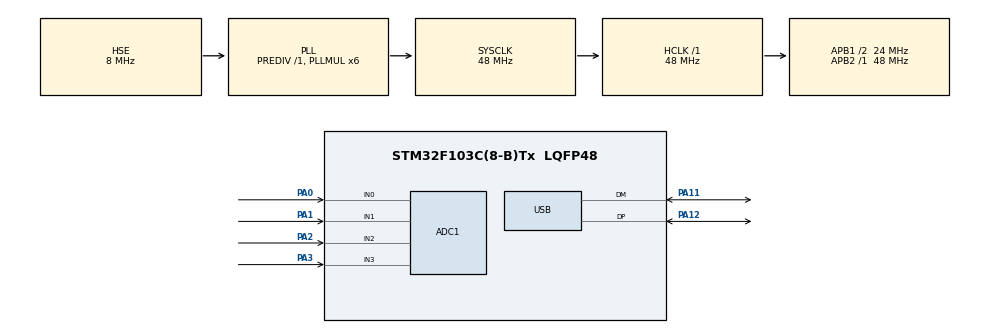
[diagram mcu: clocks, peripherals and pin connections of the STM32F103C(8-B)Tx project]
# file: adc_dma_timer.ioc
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ADC1.Channel-0\#ChannelRegularConversion=ADC_CHANNEL_0
ADC1.Channel-1\#ChannelRegularConversion=ADC_CHANNEL_1
ADC1.Channel-2\#ChannelRegularConversion=ADC_CHANNEL_2
ADC1.Channel-3\#ChannelRegularConversion=ADC_CHANNEL_3
ADC1.ExternalTrigConv=ADC_EXTERNALTRIGCONV_T3_TRGO
ADC1.NbrOfConversion=4
ADC1.NbrOfConversionFlag=1
ADC1.Rank-0\#ChannelRegularConversion=1
ADC1.Rank-1\#ChannelRegularConversion=2
ADC1.Rank-2\#ChannelRegularConversion=3
ADC1.Rank-3\#ChannelRegularConversion=4
ADC1.SamplingTime-0\#ChannelRegularConversion=ADC_SAMPLETIME_7CYCLES_5
ADC1.SamplingTime-1\#ChannelRegularConversion=ADC_SAMPLETIME_28CYCLES_5
ADC1.SamplingTime-2\#ChannelRegularConversion=ADC_SAMPLETIME_55CYCLES_5
ADC1.SamplingTime-3\#ChannelRegularConversion=ADC_SAMPLETIME_239CYCLES_5
ADC1.master=1
Dma.ADC1.0.Direction=DMA_PERIPH_TO_MEMORY
Dma.ADC1.0.Instance=DMA1_Channel1
Dma.ADC1.0.MemDataAlignment=DMA_MDATAALIGN_HALFWORD
Dma.ADC1.0.MemInc=DMA_MINC_ENABLE
Dma.ADC1.0.Mode=DMA_CIRCULAR
Dma.ADC1.0.PeriphDataAlignment=DMA_PDATAALIGN_HALFWORD
Dma.ADC1.0.PeriphInc=DMA_PINC_DISABLE
Dma.ADC1.0.Priority=DMA_PRIORITY_LOW
Dma.Request0=ADC1
Mcu.Family=STM32F1
Mcu.Name=STM32F103C(8-B)Tx
Mcu.Package=LQFP48
NVIC.ADC1_2_IRQn=true\:0\:0\:false\:false\:true\:true\:true\:true
NVIC.DMA1_Channel1_IRQn=true\:0\:0\:false\:false\:true\:false\:true\:true
NVIC.PriorityGroup=NVIC_PRIORITYGROUP_4
NVIC.USB_HP_CAN1_TX_IRQn=true\:0\:0\:false\:false\:true\:true\:true\:true
NVIC.USB_LP_CAN1_RX0_IRQn=true\:0\:0\:false\:false\:true\:false\:true\:true
PA0-WKUP.Signal=ADCx_IN0
PA1.Signal=ADCx_IN1
PA11.Mode=Device
PA11.Signal=USB_DM
PA12.Mode=Device
PA12.Signal=USB_DP
PA2.Signal=ADCx_IN2
PA3.Signal=ADCx_IN3
PD0-OSC_IN.Mode=HSE-External-Oscillator
PD0-OSC_IN.Signal=RCC_OSC_IN
PD1-OSC_OUT.Mode=HSE-External-Oscillator
PD1-OSC_OUT.Signal=RCC_OSC_OUT
ProjectManager.HeapSize=0x200
ProjectManager.StackSize=0x400
ProjectManager.TargetToolchain=STM32CubeIDE
RCC.ADCPresc=RCC_ADCPCLK2_DIV4
RCC.AHBFreq_Value=48000000
RCC.APB1CLKDivider=RCC_HCLK_DIV2
RCC.APB1Freq_Value=24000000
RCC.APB1TimFreq_Value=48000000
RCC.APB2Freq_Value=48000000
RCC.APB2TimFreq_Value=48000000
RCC.HCLKFreq_Value=48000000
RCC.PLLMUL=RCC_PLL_MUL6
RCC.SYSCLKFreq_VALUE=48000000
RCC.SYSCLKSource=RCC_SYSCLKSOURCE_PLLCLK
RCC.USBFreq_Value=48000000
SH.ADCx_IN0.0=ADC1_IN0,IN0
SH.ADCx_IN1.0=ADC1_IN1,IN1
SH.ADCx_IN2.0=ADC1_IN2,IN2
SH.ADCx_IN3.0=ADC1_IN3,IN3
TIM3.Period=1000-1
TIM3.Prescaler=24000-1
TIM3.TIM_MasterOutputTrigger=TIM_TRGO_UPDATE
TIM3.TIM_MasterSlaveMode=TIM_MASTERSLAVEMODE_ENABLE
USB_DEVICE.CLASS_NAME_FS=CDC
USB_DEVICE.PRODUCT_STRING_CDC_FS=STM32 Virtual Port
USB_DEVICE.VirtualMode=Cdc
USB_DEVICE.VirtualModeFS=Cdc_FS
VP_TIM3_VS_ClockSourceINT.Mode=Internal
VP_USB_DEVICE_VS_USB_DEVICE_CDC_FS.Mode=CDC_FS
board=custom

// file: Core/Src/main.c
/* USER CODE BEGIN Header */
/**
  ******************************************************************************
  * @file           : main.c
  * @brief          : Main program body
  ******************************************************************************
  * @attention
  *
  * Copyright (c) 2022 STMicroelectronics.
  * All rights reserved.
  *
  * This software is licensed under terms that can be found in the LICENSE file
  * in the root directory of this software component.
  * If no LICENSE file comes with this software, it is provided AS-IS.
  *
  ******************************************************************************
  */
/* USER CODE END Header */
#include "main.h"
#include "usb_device.h"

/* USER CODE BEGIN Includes */
#include "usbd_cdc_if.h"
#include "string.h"
#include "stdlib.h"
/* USER CODE END Includes */

ADC_HandleTypeDef hadc1;
DMA_HandleTypeDef hdma_adc1;

TIM_HandleTypeDef htim3;

void SystemClock_Config(void);
static void MX_GPIO_Init(void);
static void MX_DMA_Init(void);
static void MX_ADC1_Init(void);
static void MX_TIM3_Init(void);

/* USER CODE BEGIN 0 */
 uint16_t adc_val[4];

 uint8_t voltage_1[28];
 uint8_t voltage_2[28];
 uint8_t current_1[28];
 uint8_t current_2[28];

 volatile uint8_t waitForConv = 0;
 extern USBD_HandleTypeDef hUsbDeviceFS;

/* USER CODE END 0 */

int main(void)
{

  /* MCU Configuration--------------------------------------------------------*/

  /* Reset of all peripherals, Initializes the Flash interface and the Systick. */
  HAL_Init();

  /* Configure the system clock */
  SystemClock_Config();

  /* Initialize all configured peripherals */
  MX_GPIO_Init();
  MX_DMA_Init();
  MX_ADC1_Init();
  MX_TIM3_Init();
  MX_USB_DEVICE_Init();
  /* USER CODE BEGIN 2 */

HAL_ADCEx_Calibration_Start(&hadc1);
HAL_TIM_Base_Start(&htim3);
HAL_ADC_Start_DMA(&hadc1,(uint32_t*)adc_val,4);
  /* USER CODE END 2 */

  /* Infinite loop */
  while (1)
  {

	  while(waitForConv == 0) {}
	  waitForConv = 0;
	  adc_val[2]/=(.06*18);
	  	adc_val[3]/=(.06*18);

	  		sprintf((char*)voltage_1,"value of voltage_1 is = %d\n",adc_val[0]);
	  		CDC_Transmit_FS(voltage_1,28);
	  		while(((USBD_CDC_HandleTypeDef*)hUsbDeviceFS.pClassData)->TxState != 0){}
	  		sprintf(voltage_2,"value of voltage_2 is = %d\n",adc_val[1]);
	  		CDC_Transmit_FS(voltage_2,28);
	  		while(((USBD_CDC_HandleTypeDef*)hUsbDeviceFS.pClassData)->TxState != 0){}
	  		 sprintf(current_1,"value of current_1 is = %d\n",adc_val[2]);
	  		 CDC_Transmit_FS(current_1,28);
	  		while(((USBD_CDC_HandleTypeDef*)hUsbDeviceFS.pClassData)->TxState != 0){}
	  		sprintf(current_2,"value of current_2 is = %d\n",adc_val[3]);
	  		CDC_Transmit_FS(current_2,28);

  }
}

void HAL_ADC_ConvCpltCallback(ADC_HandleTypeDef* hadc)
{
	waitForConv = 1;
}

void SystemClock_Config(void)
{
  RCC_OscInitTypeDef RCC_OscInitStruct = {0};
  RCC_ClkInitTypeDef RCC_ClkInitStruct = {0};
  RCC_PeriphCLKInitTypeDef PeriphClkInit = {0};

  /** Initializes the RCC Oscillators according to the specified parameters
  * in the RCC_OscInitTypeDef structure.
  */
  RCC_OscInitStruct.OscillatorType = RCC_OSCILLATORTYPE_HSE;
  RCC_OscInitStruct.HSEState = RCC_HSE_ON;
  RCC_OscInitStruct.HSEPredivValue = RCC_HSE_PREDIV_DIV1;
  RCC_OscInitStruct.HSIState = RCC_HSI_ON;
  RCC_OscInitStruct.PLL.PLLState = RCC_PLL_ON;
  RCC_OscInitStruct.PLL.PLLSource = RCC_PLLSOURCE_HSE;
  RCC_OscInitStruct.PLL.PLLMUL = RCC_PLL_MUL6;
  if (HAL_RCC_OscConfig(&RCC_OscInitStruct) != HAL_OK)
  {
    Error_Handler();
  }

  /* convert decimal value to each digits */

  /** Initializes the CPU, AHB and APB buses clocks
  */
  RCC_ClkInitStruct.ClockType = RCC_CLOCKTYPE_HCLK|RCC_CLOCKTYPE_SYSCLK
                              |RCC_CLOCKTYPE_PCLK1|RCC_CLOCKTYPE_PCLK2;
  RCC_ClkInitStruct.SYSCLKSource = RCC_SYSCLKSOURCE_PLLCLK;
  RCC_ClkInitStruct.AHBCLKDivider = RCC_SYSCLK_DIV1;
  RCC_ClkInitStruct.APB1CLKDivider = RCC_HCLK_DIV2;
  RCC_ClkInitStruct.APB2CLKDivider = RCC_HCLK_DIV1;

  if (HAL_RCC_ClockConfig(&RCC_ClkInitStruct, FLASH_LATENCY_1) != HAL_OK)
  {
    Error_Handler();
  }
  PeriphClkInit.PeriphClockSelection = RCC_PERIPHCLK_ADC|RCC_PERIPHCLK_USB;
  PeriphClkInit.AdcClockSelection = RCC_ADCPCLK2_DIV4;
  PeriphClkInit.UsbClockSelection = RCC_USBCLKSOURCE_PLL;
  if (HAL_RCCEx_PeriphCLKConfig(&PeriphClkInit) != HAL_OK)
  {
    Error_Handler();
  }
}

static void MX_ADC1_Init(void)
{

  ADC_ChannelConfTypeDef sConfig = {0};

  /** Common config
  */
  hadc1.Instance = ADC1;
  hadc1.Init.ScanConvMode = ADC_SCAN_ENABLE;
  hadc1.Init.ContinuousConvMode = DISABLE;
  hadc1.Init.DiscontinuousConvMode = DISABLE;
  hadc1.Init.ExternalTrigConv = ADC_EXTERNALTRIGCONV_T3_TRGO;
  hadc1.Init.DataAlign = ADC_DATAALIGN_RIGHT;
  hadc1.Init.NbrOfConversion = 4;
  if (HAL_ADC_Init(&hadc1) != HAL_OK)
  {
    Error_Handler();
  }

  /** Configure Regular Channel
  */
  sConfig.Channel = ADC_CHANNEL_0;
  sConfig.Rank = ADC_REGULAR_RANK_1;
  sConfig.SamplingTime = ADC_SAMPLETIME_7CYCLES_5;
  if (HAL_ADC_ConfigChannel(&hadc1, &sConfig) != HAL_OK)
  {
    Error_Handler();
  }

  /** Configure Regular Channel
  */
  sConfig.Channel = ADC_CHANNEL_1;
  sConfig.Rank = ADC_REGULAR_RANK_2;
  sConfig.SamplingTime = ADC_SAMPLETIME_28CYCLES_5;
  if (HAL_ADC_ConfigChannel(&hadc1, &sConfig) != HAL_OK)
  {
    Error_Handler();
  }

  /** Configure Regular Channel
  */
  sConfig.Channel = ADC_CHANNEL_2;
  sConfig.Rank = ADC_REGULAR_RANK_3;
  sConfig.SamplingTime = ADC_SAMPLETIME_55CYCLES_5;
  if (HAL_ADC_ConfigChannel(&hadc1, &sConfig) != HAL_OK)
  {
    Error_Handler();
  }

  /** Configure Regular Channel
  */
  sConfig.Channel = ADC_CHANNEL_3;
  sConfig.Rank = ADC_REGULAR_RANK_4;
  sConfig.SamplingTime = ADC_SAMPLETIME_239CYCLES_5;
  if (HAL_ADC_ConfigChannel(&hadc1, &sConfig) != HAL_OK)
  {
    Error_Handler();
  }

}

static void MX_TIM3_Init(void)
{

  TIM_ClockConfigTypeDef sClockSourceConfig = {0};
  TIM_MasterConfigTypeDef sMasterConfig = {0};

  htim3.Instance = TIM3;
  htim3.Init.Prescaler = 24000-1;
  htim3.Init.CounterMode = TIM_COUNTERMODE_UP;
  htim3.Init.Period = 1000-1;
  htim3.Init.ClockDivision = TIM_CLOCKDIVISION_DIV1;
  htim3.Init.AutoReloadPreload = TIM_AUTORELOAD_PRELOAD_DISABLE;
  if (HAL_TIM_Base_Init(&htim3) != HAL_OK)
  {
    Error_Handler();
  }
  sClockSourceConfig.ClockSource = TIM_CLOCKSOURCE_INTERNAL;
  if (HAL_TIM_ConfigClockSource(&htim3, &sClockSourceConfig) != HAL_OK)
  {
    Error_Handler();
  }
  sMasterConfig.MasterOutputTrigger = TIM_TRGO_UPDATE;
  sMasterConfig.MasterSlaveMode = TIM_MASTERSLAVEMODE_ENABLE;
  if (HAL_TIMEx_MasterConfigSynchronization(&htim3, &sMasterConfig) != HAL_OK)
  {
    Error_Handler();
  }

}

static void MX_DMA_Init(void)
{

  /* DMA controller clock enable */
  __HAL_RCC_DMA1_CLK_ENABLE();

  /* DMA interrupt init */
  /* DMA1_Channel1_IRQn interrupt configuration */
  HAL_NVIC_SetPriority(DMA1_Channel1_IRQn, 0, 0);
  HAL_NVIC_EnableIRQ(DMA1_Channel1_IRQn);

}

static void MX_GPIO_Init(void)
{

  /* GPIO Ports Clock Enable */
  __HAL_RCC_GPIOD_CLK_ENABLE();
  __HAL_RCC_GPIOA_CLK_ENABLE();

}

void Error_Handler(void)
{
  __disable_irq();
  while (1)
  {
  }
}
